# CH32V205 register map
Vendor: WCH Ltd.; File version: 1.0
Registers are 32-bit, read-write, reset 0x0 unless marked. A register's access mark holds for its fields unless they carry their own. Offsets are from the block's base; [hi:lo] are bit positions; {n}, {i} and the like mark numbered series.

## RCC — Reset and clock control
Base 0x40021000
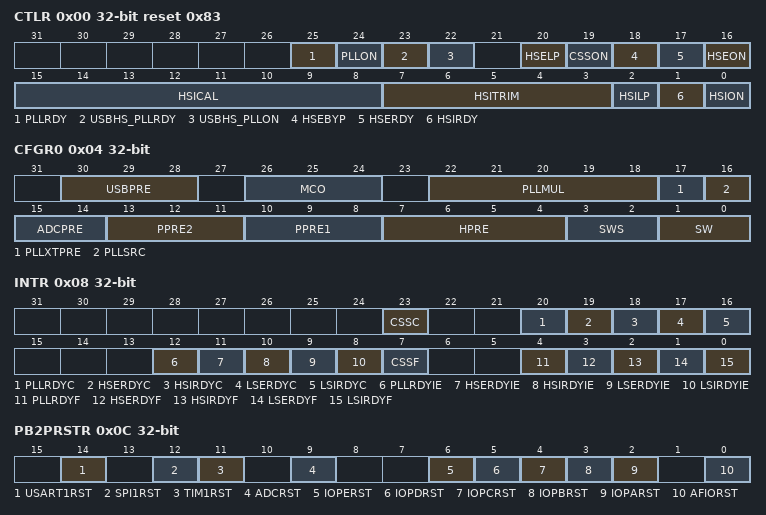
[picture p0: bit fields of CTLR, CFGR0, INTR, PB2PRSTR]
0x00 CTLR access per field reset 0x83 — Clock control register
  [25] PLLRDY ro — PLL clock ready flag
  [24] PLLON rw — PLL enable
  [23] USBHS_PLLRDY ro — USBHS PLL clock ready flag
  [22] USBHS_PLLON rw — USBHS PLL enable
  [20] HSELP rw — HSE low-power mode
  [19] CSSON rw — Clock Security System enable
  [18] HSEBYP rw — External High Speed clock Bypass
  [17] HSERDY ro — External High Speed clock ready flag
  [16] HSEON rw — External High Speed clock enable
  [15:8] HSICAL ro — Internal High Speed clock Calibration
  [7:3] HSITRIM rw — Internal High Speed clock trimming
  [2] HSILP ro — HSI Internal low-power mode
  [1] HSIRDY ro — HSI Internal High Speed clock ready flag
  [0] HSION rw — Internal High Speed clock enable
0x04 CFGR0 access per field — Clock configuration register (RCC_CFGR0)
  [30:28] USBPRE rw — USB prescaler
  [26:24] MCO rw — Microcontroller clock output
  [22:18] PLLMUL rw — PLL Multiplication Factor
  [17] PLLXTPRE rw — HSE divider for PLL entry
  [16] PLLSRC rw — PLL entry clock source
  [15:14] ADCPRE rw — ADC prescaler
  [13:11] PPRE2 rw — PB High speed prescaler (PB2)
  [10:8] PPRE1 rw — PB Low speed prescaler (PB1)
  [7:4] HPRE rw — HB prescaler
  [3:2] SWS ro — System Clock Switch Status
  [1:0] SW rw — System clock Switch
0x08 INTR access per field — Clock interrupt register (RCC_INTR)
  [23] CSSC wo — Clock security system interrupt clear
  [20] PLLRDYC wo — PLL Ready Interrupt Clear
  [19] HSERDYC wo — HSE Ready Interrupt Clear
  [18] HSIRDYC wo — HSI Ready Interrupt Clear
  [17] LSERDYC wo — LSE Ready Interrupt Clear
  [16] LSIRDYC wo — LSI Ready Interrupt Clear
  [12] PLLRDYIE rw — PLL Ready Interrupt Enable
  [11] HSERDYIE rw — HSE Ready Interrupt Enable
  [10] HSIRDYIE rw — HSI Ready Interrupt Enable
  [9] LSERDYIE rw — LSE Ready Interrupt Enable
  [8] LSIRDYIE rw — LSI Ready Interrupt Enable
  [7] CSSF ro — Clock Security System Interrupt flag
  [4] PLLRDYF ro — PLL Ready Interrupt flag
  [3] HSERDYF ro — HSE Ready Interrupt flag
  [2] HSIRDYF ro — HSI Ready Interrupt flag
  [1] LSERDYF ro — LSE Ready Interrupt flag
  [0] LSIRDYF ro — LSI Ready Interrupt flag
0x0C PB2PRSTR — PB2 peripheral reset register (RCC_PB2PRSTR)
  [14] USART1RST — USART1 reset
  [12] SPI1RST — SPI 1 reset
  [11] TIM1RST — TIM1 timer reset
  [9] ADCRST — ADC 1 interface reset
  [6] IOPERST — IO port E reset
  [5] IOPDRST — IO port D reset
  [4] IOPCRST — IO port C reset
  [3] IOPBRST — IO port B reset
  [2] IOPARST — IO port A reset
  [0] AFIORST — Alternate function I/O reset
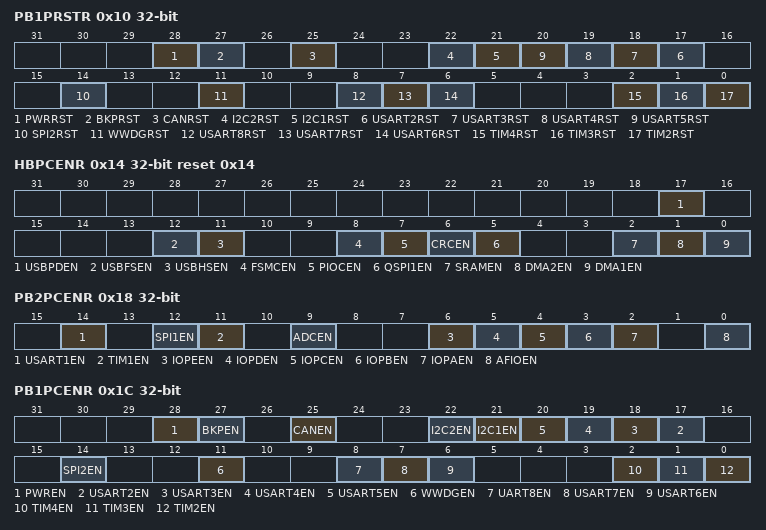
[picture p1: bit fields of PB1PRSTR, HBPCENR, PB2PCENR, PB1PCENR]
0x10 PB1PRSTR — PB1 peripheral reset register (RCC_PB1PRSTR)
  [28] PWRRST — Power interface reset
  [27] BKPRST — Backup interface reset
  [25] CANRST — CAN reset
  [22] I2C2RST — I2C2 reset
  [21] I2C1RST — I2C1 reset
  [n+15] USART{n}RST (n=2..5) — USART {n} reset
  [14] SPI2RST — SPI2 reset
  [11] WWDGRST — Window watchdog reset
  [8] USART8RST — USART 8 reset
  [7] USART7RST — USART 7 reset
  [6] USART6RST — USART 6 reset
  [2] TIM4RST — Timer 4 reset
  [1] TIM3RST — Timer 3 reset
  [0] TIM2RST — Timer 2 reset
0x14 HBPCENR reset 0x14 — HB Peripheral Clock enable register (RCC_HBPCENR)
  [17] USBPDEN — USBPD clock enable
  [12] USBFSEN — USBFSEN clock enable
  [11] USBHSEN — USBHS clock enable
  [8] FSMCEN — FSMC clock enable
  [7] PIOCEN — PIOC clock enable
  [6] CRCEN — CRC clock enable
  [5] QSPI1EN — QSPI1 interface clock enable
  [2] SRAMEN — SRAM interface clock enable
  [1] DMA2EN — DMA2 clock enable
  [0] DMA1EN — DMA1 clock enable
0x18 PB2PCENR — PB2 peripheral clock enable register (RCC_PB2PCENR)
  [14] USART1EN — USART1 clock enable
  [12] SPI1EN — SPI 1 clock enable
  [11] TIM1EN — TIM1 Timer clock enable
  [9] ADCEN — ADC interface clock enable
  [6] IOPEEN — I/O port E clock enable
  [5] IOPDEN — I/O port D clock enable
  [4] IOPCEN — I/O port C clock enable
  [3] IOPBEN — I/O port B clock enable
  [2] IOPAEN — I/O port A clock enable
  [0] AFIOEN — Alternate function I/O clock enable
0x1C PB1PCENR — PB1 peripheral clock enable register (RCC_PB1PCENR)
  [28] PWREN — Power interface clock enable
  [27] BKPEN — Backup interface clock enable
  [25] CANEN — CAN clock enable
  [22] I2C2EN — I2C 2 clock enable
  [21] I2C1EN — I2C 1 clock enable
  [n+15] USART{n}EN (n=2..5) — USART {n} clock enable
  [14] SPI2EN — SPI 2 clock enable
  [11] WWDGEN — Window watchdog clock enable
  [8] UART8EN — USART 8 clock enable
  [7] USART7EN — USART 7 clock enable
  [6] USART6EN — USART 6 clock enable
  [2] TIM4EN — Timer 4 clock enable
  [1] TIM3EN — Timer 3 clock enable
  [0] TIM2EN — Timer 2 clock enable
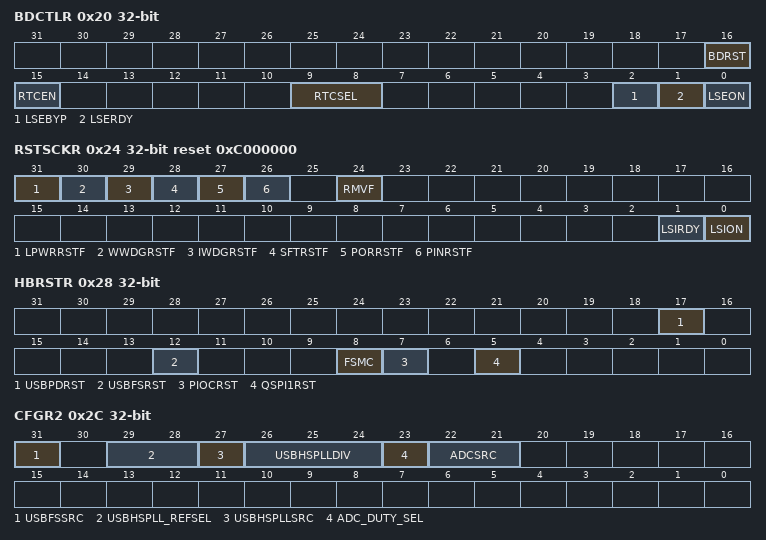
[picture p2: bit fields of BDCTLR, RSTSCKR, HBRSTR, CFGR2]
0x20 BDCTLR access per field — Backup domain control register (RCC_BDCTLR)
  [16] BDRST rw — Backup domain software reset
  [15] RTCEN ro — RTC clock enable
  [9:8] RTCSEL ro — RTC clock source selection
  [2] LSEBYP ro — External Low Speed oscillator bypass
  [1] LSERDY ro — External Low Speed oscillator ready
  [0] LSEON ro — External Low Speed oscillator enable
0x24 RSTSCKR access per field reset 0xC000000 — Control/status register (RCC_RSTSCKR)
  [31] LPWRRSTF ro — Low-power reset flag
  [30] WWDGRSTF ro — Window watchdog reset flag
  [29] IWDGRSTF ro — Independent watchdog reset flag
  [28] SFTRSTF ro — Software reset flag
  [27] PORRSTF ro — POR/PDR reset flag
  [26] PINRSTF ro — PIN reset flag
  [24] RMVF wo — Remove reset flag
  [1] LSIRDY ro — Internal low speed oscillator ready
  [0] LSION rw — Internal low speed oscillator enable
0x28 HBRSTR — HB reset register (RCC_APHBRSTR)
  [17] USBPDRST — USBPD reset control
  [12] USBFSRST — USBFD reset control
  [8] FSMC — FSMC reset control
  [7] PIOCRST — PIOC reset control
  [5] QSPI1RST — QSPI1 reset control
0x2C CFGR2 — Clock configuration register (RCC_CFGR2)
  [31] USBFSSRC — USBFS clock source selection
  [29:28] USBHSPLL_REFSEL — USBHS_PLL reference clock frequency selection
  [27] USBHSPLLSRC — USBHS_PLL clock source selection
  [26:24] USBHSPLLDIV — USBHS_PLL clock source division
  [23] ADC_DUTY_SEL — ADC clock duty cycle selection
  [22:21] ADCSRC — ADC clock source selection
